VERSION ""

NS_ :

BS_:

BU_: CAS GWS

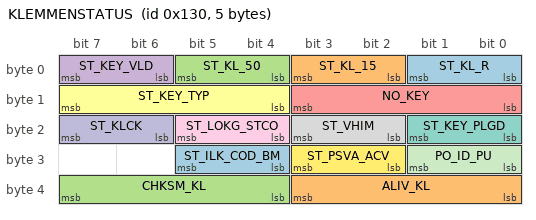
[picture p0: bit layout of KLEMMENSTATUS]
BO_ 304 KLEMMENSTATUS: 5 CAS
 SG_ ST_KL_R : 0|2@1+ (1,0) [0|0] "status terminal R"  CAS
 SG_ ST_KL_15 : 2|2@1+ (1,0) [0|0] "status terminal 15"  CAS
 SG_ ST_KL_50 : 4|2@1+ (1,0) [0|0] "status terminal 50"  CAS
 SG_ ST_KEY_VLD : 6|2@1+ (1,0) [0|0] "status valid key"  CAS
 SG_ NO_KEY : 8|4@1+ (1,0) [0|0] "key number"  CAS
 SG_ ST_KEY_TYP : 12|4@1+ (1,0) [0|0] ""  CAS
 SG_ ST_KEY_PLGD : 16|2@1+ (1,0) [0|0] ""  CAS
 SG_ ST_VHIM : 18|2@1+ (1,0) [0|0] "Status immobilizer"  CAS
 SG_ ST_LOKG_STCO : 20|2@1+ (1,0) [0|0] ""  CAS
 SG_ ST_KLCK : 22|2@1+ (1,0) [0|0] ""  CAS
 SG_ PO_ID_PU : 24|2@1+ (1,0) [0|0] ""  CAS
 SG_ ST_PSVA_ACV : 26|2@1+ (1,0) [0|0] ""  CAS
 SG_ ST_ILK_COD_BM : 28|2@1+ (1,0) [0|0] ""  CAS
 SG_ ALIV_KL : 32|4@1+ (1,0) [0|14] "Alive counter"  CAS
 SG_ CHKSM_KL : 36|4@1+ (1,0) [0|15] "Checksum"  CAS

BO_ 1246 NETZWERKMANAGEMENT_GWS: 8 GWS
 SG_ Byte0 : 0|8@1+ (1,0) [0|0] "Netzwerkmanagement_Byte0"  GWS

BO_ 408 BEDIENUNG_GWS2: 5 GWS
 SG_ Byte0 : 0|4@1+ (1,0) [0|0] "Bedienung_Byte0"  GWS
 SG_ ALIV_KL : 4|4@1+ (1,0) [0|14] "Alive counter"  CAS

BA_DEF_ BO_  "GenMsgBackgroundColor" STRING ;
BA_DEF_ BO_  "GenMsgForegroundColor" STRING ;
BA_DEF_DEF_  "GenMsgBackgroundColor" "#ffffff";
BA_DEF_DEF_  "GenMsgForegroundColor" "#000000";
